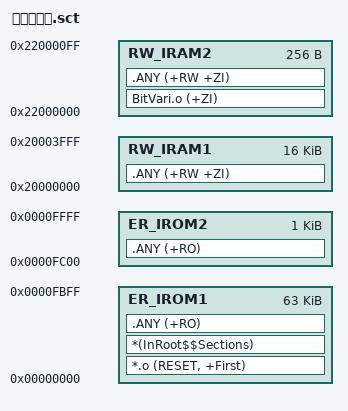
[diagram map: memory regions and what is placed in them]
; *************************************************************
; *** Scatter-Loading Description File generated by uVision ***
; *************************************************************

LR_IROM1 0x00000000 0x0000FC00
 {; 程序首址 和 FLASH 长度
  ER_IROM1 0x00000000 0x0000FC00 
   {; 程序装载和执行地址
    *.o (RESET, +First)
    *(InRoot$$Sections)
    .ANY (+RO)
   }
  RW_IRAM1 0x20000000 0x00004000 
   {; RW data
    .ANY (+RW +ZI)
   }
  RW_IRAM2 0x22000000 0x00000100 
   {; RW data
    BitVari.o (+ZI)
    .ANY (+RW +ZI)
   }
}
LR_IROM2 0x0000FC00 0x00000400  
 {;表位号保存地址
  ER_IROM2 0x0000FC00 0x00000400
   {
    .ANY (+RO)
   }
}
